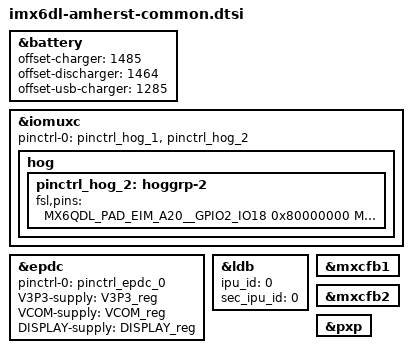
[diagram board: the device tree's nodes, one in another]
/*
 * Copyright (C) 2014 Freescale Semiconductor, Inc.
 *
 * This program is free software; you can redistribute it and/or modify
 * it under the terms of the GNU General Public License version 2 as
 * published by the Free Software Foundation.
 */

&battery {
	offset-charger = <1485>;
	offset-discharger = <1464>;
	offset-usb-charger = <1285>;
};

&iomuxc {
	pinctrl-names = "default";
	pinctrl-0 = <&pinctrl_hog_1>, <&pinctrl_hog_2>;

	hog {
		pinctrl_hog_2: hoggrp-2 {
			fsl,pins = <
				/* elan touch */
				MX6QDL_PAD_EIM_A20__GPIO2_IO18 0x80000000
				MX6QDL_PAD_EIM_DA8__GPIO3_IO08 0x80000000
				MX6QDL_PAD_EIM_D28__GPIO3_IO28 0x170b0
			>;
		};
	};
};

&epdc {
	pinctrl-names = "default";
	pinctrl-0 = <&pinctrl_epdc_0>;
	V3P3-supply = <&V3P3_reg>;
	VCOM-supply = <&VCOM_reg>;
	DISPLAY-supply = <&DISPLAY_reg>;
	status = "okay";
};

&ldb {
	ipu_id = <0>;
	sec_ipu_id = <0>;
};

&mxcfb1 {
	status = "okay";
};

&mxcfb2 {
	status = "okay";
};

&pxp {
	status = "okay";
};
